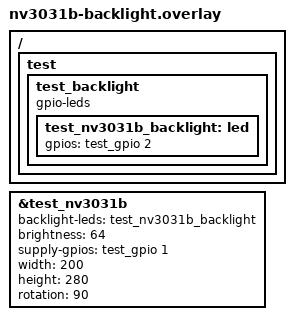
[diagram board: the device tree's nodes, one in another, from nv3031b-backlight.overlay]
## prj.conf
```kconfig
CONFIG_TEST=y
CONFIG_EMUL=y
CONFIG_SPI=y
CONFIG_GPIO=y
CONFIG_DISPLAY=y
CONFIG_MIPI_DSI=y
CONFIG_MSPI=y
CONFIG_PWM=y
```

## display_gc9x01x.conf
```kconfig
CONFIG_GC9X01X=y
```

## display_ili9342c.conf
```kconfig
CONFIG_ILI9342C=y
```

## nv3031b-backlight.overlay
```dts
/*
 * SPDX-FileCopyrightText: Copyright The Zephyr Project Contributors
 * SPDX-License-Identifier: Apache-2.0
 */

/ {
	test {
		test_backlight {
			compatible = "gpio-leds";

			test_nv3031b_backlight: led {
				gpios = <&test_gpio 2 0>;
			};
		};
	};
};

&test_nv3031b {
	backlight-leds = <&test_nv3031b_backlight>;
	brightness = <64>;
	supply-gpios = <&test_gpio 1 0>;
	/* Exercise a different geometry and rotation in this build-only fixture. */
	width = <200>;
	height = <280>;
	rotation = <90>;
};
```

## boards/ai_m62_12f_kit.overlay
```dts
/*
 * Copyright (c) 2025 MASSDRIVER EI (massdriver.space)
 *
 * SPDX-License-Identifier: Apache-2.0
 */

&dbi0 {
	compatible = "bflb,dbi";

	dmas = <&dma0 0 0x14>;
	dma-names = "tx";
	status = "okay";
};
```

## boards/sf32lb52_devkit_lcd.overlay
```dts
/*
 * Copyright (c) 2025, Qingsong Gou <gouqs@hotmail.com>
 * SPDX-License-Identifier: Apache-2.0
 */

&pinctrl {
	lcdc_8080_default: lcdc_8080_default {
		group1 {
			pinmux = <PA03_LCDC1_8080_CS>,
				 <PA04_LCDC1_8080_WR>,
				 <PA05_LCDC1_8080_RD>,
				 <PA06_LCDC1_8080_DC>,
				 <PA07_LCDC1_8080_DIO0>,
				 <PA08_LCDC1_8080_DIO1>,
				 <PA37_LCDC1_8080_DIO2>,
				 <PA39_LCDC1_8080_DIO3>,
				 <PA40_LCDC1_8080_DIO4>,
				 <PA41_LCDC1_8080_DIO5>,
				 <PA42_LCDC1_8080_DIO6>,
				 <PA43_LCDC1_8080_DIO7>,
				 <PA02_LCDC1_8080_TE>;
			input-enable;
		};
	};
};

&lcdc {
	status = "okay";

	mipi_dbi: mipi-dbi {
		#address-cells = <1>;
		#size-cells = <0>;
		pinctrl-0 = <&lcdc_8080_default>;
		pinctrl-names = "default";
		status = "okay";
	};
};
```

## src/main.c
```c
/*
 * Copyright (c) 2022, Kumar Gala <galak@kernel.org>
 *
 * SPDX-License-Identifier: Apache-2.0
 */

#include <zephyr/drivers/mipi_dbi.h>
#include <zephyr/sys/util.h>

/*
 * ssd1322@9 is the last MIPI DBI child inside the ten cs-gpios entries this fixture's SPI
 * controller declares, and st75256@a is the first one past them. Other boards build this
 * suite with a display fixture of their own, so this is scoped to the nodes it is about.
 */
#if DT_NODE_EXISTS(DT_NODELABEL(test_mipi_dbi_ssd1322)) && \
	DT_NODE_EXISTS(DT_NODELABEL(test_mipi_dbi_st75256))
BUILD_ASSERT(MIPI_DBI_SPI_DEV_HAS_CS_GPIOS(DT_NODELABEL(test_mipi_dbi_ssd1322)),
	     "the last child inside cs-gpios must resolve to a GPIO chip select");
BUILD_ASSERT(!MIPI_DBI_SPI_DEV_HAS_CS_GPIOS(DT_NODELABEL(test_mipi_dbi_st75256)),
	     "a child past the end of cs-gpios must not resolve to a GPIO chip select");
#endif

int main(void)
{
	return 0;
}
```
